# nrf7120E_enga_flpr register map
Vendor: Nordic Semiconductor; Series: nrf71; File version: 1
Registers are 32-bit, read-write, reset 0x0 unless marked. A register's access mark holds for its fields unless they carry their own. Offsets are from the block's base; [hi:lo] are bit positions; lines under a group give offsets from that group; {n}, {i} and the like mark numbered series; 'fields as' and 'values as' point back to an identical list.

## GLOBAL_COEXC_NS — Coexistence controller 0
Base 0x400F1000
Same registers: GLOBAL_COEXC_S 0x500F1000
{0x400+0x20*i} CCMALLOW[{i}] (i=0..7) group — Unspecified
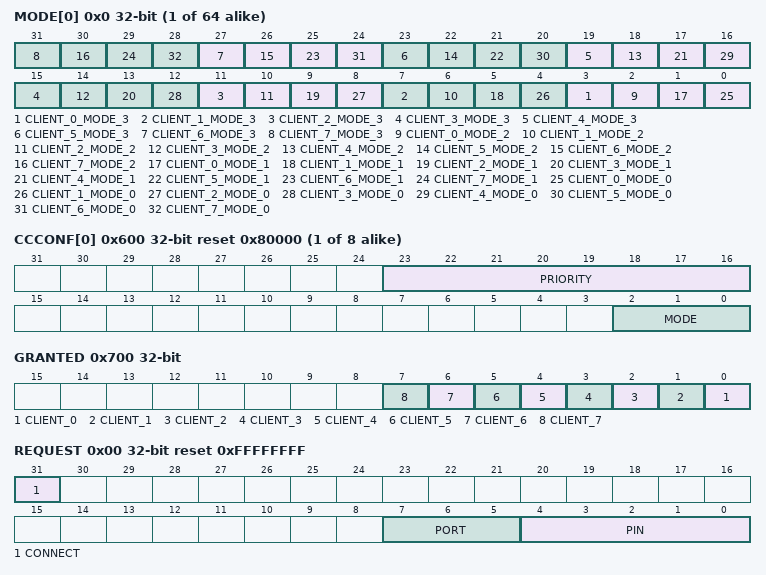
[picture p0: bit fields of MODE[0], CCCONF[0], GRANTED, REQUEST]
  {0x0+4j} MODE[{j}] (j=0..7) — Description collection: Coexistence client mode allow configuration for mode [o] in client [n]
    [all] fields
      0=NotAllowed (Coexistence not allowed); 1=Allow (Coexistence allowed)
    [4n+3] CLIENT_{n}_MODE_3 (n=0..7) — Coexistence allowed configuration for mode [3] in client [{n}]
    [4n+2] CLIENT_{n}_MODE_2 (n=0..7) — Coexistence allowed configuration for mode [2] in client [{n}]
    [4n+1] CLIENT_{n}_MODE_1 (n=0..7) — Coexistence allowed configuration for mode [1] in client [{n}]
    [4n] CLIENT_{n}_MODE_0 (n=0..7) — Coexistence allowed configuration for mode [0] in client [{n}]
{0x600+4i} CCCONF[{i}] (i=0..7) reset 0x80000 — Description collection: Configuration of coexistence client [n]
  [23:16] PRIORITY — Priority of the coexistence client [n]
  [2:0] MODE — Coexistence mode of the client [n]
{0x640+4i} TURNAROUND[{i}] (i=0..7) reset 0x280 — Description collection: Turnaround time for the coexistence client [n]
  [11:0] CLOCKCYCLES — Number of clock cycles
0x700 GRANTED ro — Granted status of the shared resource
  [n] CLIENT_{n} (n=0..7) — Granted status of coexistence clients
    0=NotGranted (Shared resource is not granted for coexistence client [{n}]); 1=Granted (Shared resource is granted for coexistence client [{n}])
0x704 PSEL group — Unspecified
  0x00 REQUEST reset 0xFFFFFFFF — Pin select for extRequest signal
    [31] CONNECT — Connection
      1=Disconnected; 0=Connected
    [7:5] PORT — Port number
    [4:0] PIN — Pin number
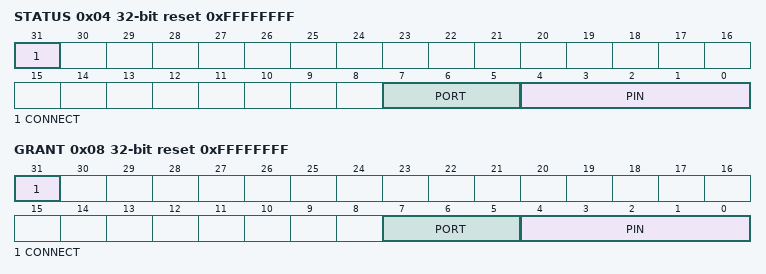
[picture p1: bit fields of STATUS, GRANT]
  0x04 STATUS reset 0xFFFFFFFF — Pin select for extStatus signal
    fields as PSEL.REQUEST
  0x08 GRANT reset 0xFFFFFFFF — Pin select for extGrant signal
    fields as PSEL.REQUEST

## GLOBAL_WDT30_S — Watchdog Timer 0
Base 0x50108000
Same registers: GLOBAL_WDT31_NS 0x40109000, GLOBAL_WDT31_S 0x50109000
0x00 TASKS_START wo — Start WDT
  [0] TASKS_START
    1=Trigger task
0x04 TASKS_STOP wo — Stop WDT
  [0] TASKS_STOP
    1=Trigger task
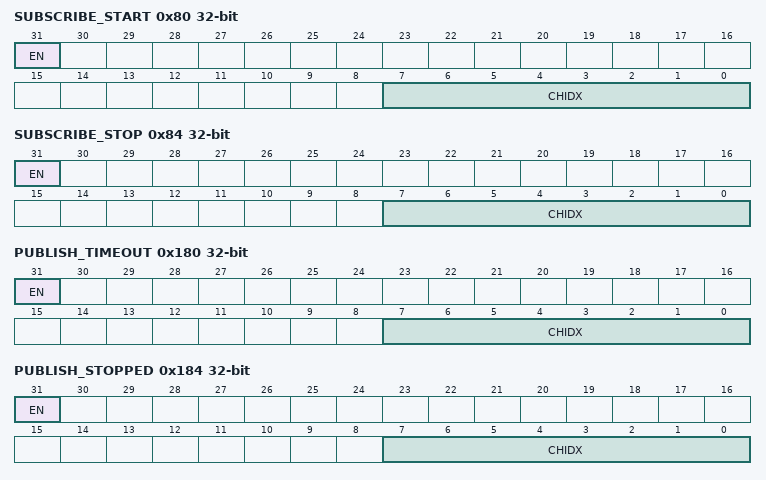
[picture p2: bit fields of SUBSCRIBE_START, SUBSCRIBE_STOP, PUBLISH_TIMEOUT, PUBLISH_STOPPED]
0x80 SUBSCRIBE_START — Subscribe configuration for task START
  [31] EN
    0=Disabled (Disable subscription); 1=Enabled (Enable subscription)
  [7:0] CHIDX — DPPI channel that task START will subscribe to
0x84 SUBSCRIBE_STOP — Subscribe configuration for task STOP
  [31] EN
    values as SUBSCRIBE_START.EN
  [7:0] CHIDX — DPPI channel that task STOP will subscribe to
0x100 EVENTS_TIMEOUT — Watchdog timeout
  [0] EVENTS_TIMEOUT
    0=NotGenerated (Event not generated); 1=Generated (Event generated)
0x104 EVENTS_STOPPED — Watchdog stopped
  [0] EVENTS_STOPPED
    values as EVENTS_TIMEOUT.EVENTS_TIMEOUT
0x180 PUBLISH_TIMEOUT — Publish configuration for event TIMEOUT
  [31] EN
    0=Disabled (Disable publishing); 1=Enabled (Enable publishing)
  [7:0] CHIDX — DPPI channel that event TIMEOUT will publish to
0x184 PUBLISH_STOPPED — Publish configuration for event STOPPED
  [31] EN
    values as PUBLISH_TIMEOUT.EN
  [7:0] CHIDX — DPPI channel that event STOPPED will publish to
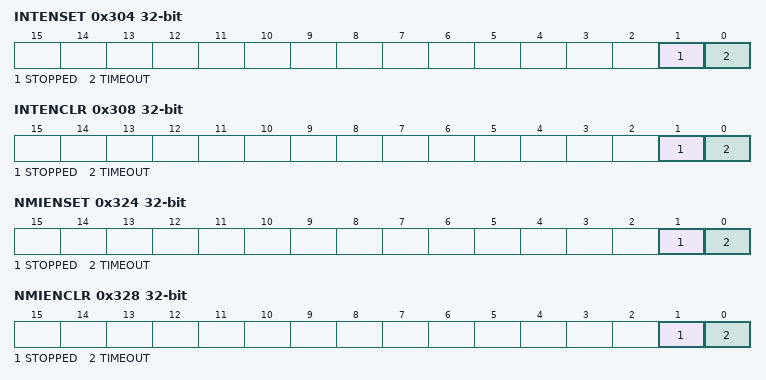
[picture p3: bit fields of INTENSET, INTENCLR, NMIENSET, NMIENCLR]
0x304 INTENSET — Enable interrupt
  [1] STOPPED write-1-sets — Write '1' to enable interrupt for event STOPPED
    on read: 0=Disabled (Read: Disabled); 1=Enabled (Read: Enabled) | on write: 1=Set (Enable)
  [0] TIMEOUT write-1-sets — Write '1' to enable interrupt for event TIMEOUT
    values as STOPPED
0x308 INTENCLR — Disable interrupt
  [1] STOPPED write-1-clears — Write '1' to disable interrupt for event STOPPED
    on read: 0=Disabled (Read: Disabled); 1=Enabled (Read: Enabled) | on write: 1=Clear (Disable)
  [0] TIMEOUT write-1-clears — Write '1' to disable interrupt for event TIMEOUT
    values as STOPPED
0x324 NMIENSET — Enable interrupt
  fields as INTENSET
0x328 NMIENCLR — Disable interrupt
  fields as INTENCLR
0x400 RUNSTATUS ro
  [0] RUNSTATUSWDT — Indicates whether or not WDT is running
    0=NotRunning (Watchdog is not running); 1=Running (Watchdog is running)
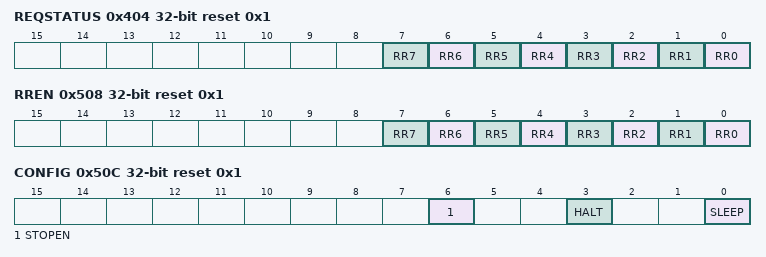
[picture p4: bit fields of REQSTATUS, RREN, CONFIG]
0x404 REQSTATUS ro reset 0x1 — Request status
  [n] RR{n} (n=0..7) — Request status for RR[{n}] register
    0=DisabledOrRequested (RR[{n}] register is not enabled, or are already requesting reload); 1=EnabledAndUnrequested (RR[{n}] register is enabled, and are not yet requesting reload)
0x504 CRV reset 0xFFFFFFFF — Counter reload value
  [31:0] CRV — Counter reload value in number of cycles of the 32.768 kHz clock
0x508 RREN reset 0x1 — Enable register for reload request registers
  [n] RR{n} (n=0..7) — Enable or disable RR[{n}] register
    0=Disabled (Disable RR[{n}] register); 1=Enabled (Enable RR[{n}] register)
0x50C CONFIG reset 0x1 — Configuration register
  [6] STOPEN — Allow stopping WDT
    0=Disable (Do not allow stopping WDT); 1=Enable (Allow stopping WDT)
  [3] HALT — Configure WDT to either be paused, or kept running, while the CPU is halted by the debugger
    0=Pause WDT while the CPU is halted by the debugger; 1=Run (Keep WDT running while the CPU is halted by the debugger)
  [0] SLEEP — Configure WDT to either be paused, or kept running, while the CPU is sleeping
    0=Pause WDT while the CPU is sleeping; 1=Run (Keep WDT running while the CPU is sleeping)
0x520 TSEN wo — Task stop enable
  [31:0] TSEN — Allow stopping WDT
    0x6E524635=Enable (Value to allow stopping WDT)
{0x600+4i} RR[{i}] (i=0..7) wo — Description collection: Reload request n
  [31:0] RR — Reload request register
    0x6E524635=Reload (Value to request a reload of the watchdog timer)

## Notices in the file
Copyright (c) 2010 - 2026, Nordic Semiconductor ASA All rights reserved.
SPDX-License-Identifier: BSD-3-Clause
Redistribution and use in source and binary forms, with or without
modification, are permitted provided that the following conditions are met:
1. Redistributions of source code must retain the above copyright notice, this
list of conditions and the following disclaimer.
2. Redistributions in binary form must reproduce the above copyright
notice, this list of conditions and the following disclaimer in the
documentation and/or other materials provided with the distribution.
3. Neither the name of Nordic Semiconductor ASA nor the names of its
contributors may be used to endorse or promote products derived from this
software without specific prior written permission.
THIS SOFTWARE IS PROVIDED BY THE COPYRIGHT HOLDERS AND CONTRIBUTORS "AS IS"
AND ANY EXPRESS OR IMPLIED WARRANTIES, INCLUDING, BUT NOT LIMITED TO, THE
IMPLIED WARRANTIES OF MERCHANTABILITY, AND FITNESS FOR A PARTICULAR PURPOSE
ARE DISCLAIMED. IN NO EVENT SHALL NORDIC SEMICONDUCTOR ASA OR CONTRIBUTORS BE
LIABLE FOR ANY DIRECT, INDIRECT, INCIDENTAL, SPECIAL, EXEMPLARY, OR
CONSEQUENTIAL DAMAGES (INCLUDING, BUT NOT LIMITED TO, PROCUREMENT OF
SUBSTITUTE GOODS OR SERVICES; LOSS OF USE, DATA, OR PROFITS; OR BUSINESS
INTERRUPTION) HOWEVER CAUSED AND ON ANY THEORY OF LIABILITY, WHETHER IN
CONTRACT, STRICT LIABILITY, OR TORT (INCLUDING NEGLIGENCE OR OTHERWISE)
ARISING IN ANY WAY OUT OF THE USE OF THIS SOFTWARE, EVEN IF ADVISED OF THE
POSSIBILITY OF SUCH DAMAGE.
